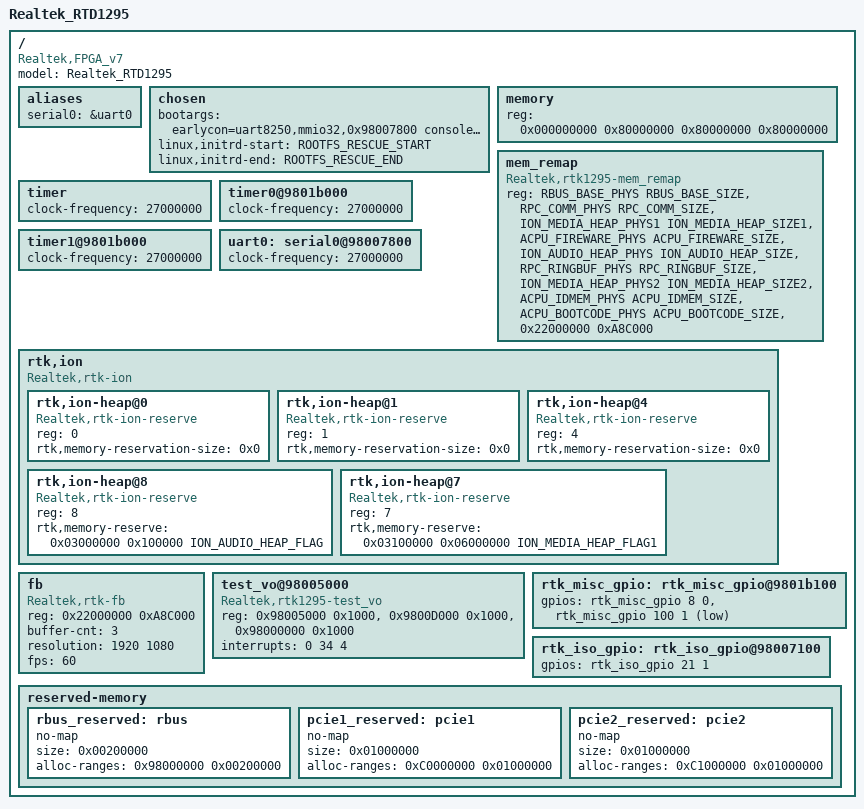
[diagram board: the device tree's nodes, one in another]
/dts-v1/;
#include "../../../../../include/soc/realtek/memory.h"

/memreserve/ SYS_BOOTCODE_MEMBASE       SYS_BOOTCODE_MEMSIZE        ; /* 0x00000000 ~ 0x00030000 */
/memreserve/ RPC_COMM_PHYS              RPC_COMM_SIZE               ; /* 0x0001f000 ~ 0x0001ffff */
/memreserve/ RESERVED_832KB_PHYS        RESERVED_832KB_SIZE         ; /* 0x00030000 ~ 0x000fffff */
/memreserve/ ACPU_FIREWARE_PHYS         ACPU_FIREWARE_SIZE          ; /* 0x01b00000 ~ 0x01efffff */
/memreserve/ RPC_RINGBUF_PHYS           RPC_RINGBUF_SIZE            ; /* 0x01ffe000 ~ 0x02001fff */
/memreserve/ ROOTFS_RESCUE_START        ROOTFS_RESCUE_SIZE          ; /* 0x02200000 ~ 0x02Dfffff */
/memreserve/ 0x22000000                 0x17BB000                   ; /* Framebuffer */
/memreserve/ 0x03000000                 0x00100000                  ; /* ?? */
/memreserve/ 0x03100000                 0x06000000                  ; /* ?? */
/memreserve/ ACPU_IDMEM_PHYS            ACPU_IDMEM_SIZE             ; /* 0x10000000 ~ 0x10013fff */
/memreserve/ ACPU_BOOTCODE_PHYS         ACPU_BOOTCODE_SIZE          ; /* 0x10000000 ~ 0x10013fff */
/memreserve/ HW_SECURE_RAM_START        HW_SECURE_RAM_SIZE          ; /* 32KB */
/memreserve/ HW_NOR_REMAP_START         HW_NOR_REMAP_SIZE           ; /* 32MB */
/memreserve/ HW_JTAG_GIC_RSV_START      HW_JTAG_GIC_RSV_SIZE        ; /* 8MB  */


#include "rtd-1296.dtsi"
#include "rtd-129x-dvfs.dtsi"

/ {
    model= "Realtek_RTD1295";
    compatible = "Realtek,FPGA_v7", "Realtek,rtd-1295";

    aliases {
        serial0 = &uart0;
    };

    chosen {
        bootargs = "earlycon=uart8250,mmio32,0x98007800 console=ttyS0,115200 cma=64m@576m init=/init androidboot.hardware=kylin androidboot.storage=emmc loglevel=4";
        linux,initrd-start = <ROOTFS_RESCUE_START>;
        linux,initrd-end = <ROOTFS_RESCUE_END>;
    };

    memory {
        device_type = "memory";
        reg = <0x000000000 0x80000000 0x80000000 0x80000000>; /* 4096 MB */
    };

    mem_remap {
        compatible = "Realtek,rtk1295-mem_remap";
        reg = <RBUS_BASE_PHYS RBUS_BASE_SIZE>,
              <RPC_COMM_PHYS RPC_COMM_SIZE>,
              <ION_MEDIA_HEAP_PHYS1 ION_MEDIA_HEAP_SIZE1>,
              <ACPU_FIREWARE_PHYS ACPU_FIREWARE_SIZE>,
              <ION_AUDIO_HEAP_PHYS ION_AUDIO_HEAP_SIZE>,
              <RPC_RINGBUF_PHYS RPC_RINGBUF_SIZE>,
              <ION_MEDIA_HEAP_PHYS2 ION_MEDIA_HEAP_SIZE2>,
              <ACPU_IDMEM_PHYS ACPU_IDMEM_SIZE>,
              <ACPU_BOOTCODE_PHYS ACPU_BOOTCODE_SIZE>,
              <0x22000000 0xA8C000>;
    };

    timer {
        clock-frequency = <27000000>;
    };

    timer0@9801b000 {
        clock-frequency = <27000000>;
    };

    timer1@9801b000 {
        clock-frequency = <27000000>;
    };

    uart0: serial0@98007800 {
        clock-frequency = <27000000>;
    };

    rtk,ion {
        compatible = "Realtek,rtk-ion";
        #address-cells = <1>;
        #size-cells = <0>;
        rtk,ion-heap@0 {    /* SYSTEM_HEAP */
            compatible = "Realtek,rtk-ion-reserve";
            reg = <0>;
            rtk,memory-reservation-size = <0x0>;
        };
        rtk,ion-heap@1 {    /* System contig */
            compatible = "Realtek,rtk-ion-reserve";
            reg = <1>;
            rtk,memory-reservation-size = <0x0>;
        };
        rtk,ion-heap@4 {    /* DMA_HEAP */
            compatible = "Realtek,rtk-ion-reserve";
            reg = <4>;
            rtk,memory-reservation-size = <0x0>;
        };
        rtk,ion-heap@8 {    /* Audio */
            compatible = "Realtek,rtk-ion-reserve";
            reg = <8>;
            rtk,memory-reserve = <
                0x03000000 0x100000 ION_AUDIO_HEAP_FLAG
                >;
        };
        rtk,ion-heap@7 {    /* TYPE_MEDIA */
            compatible = "Realtek,rtk-ion-reserve";
            reg = <7>;
            rtk,memory-reserve = <
                0x03100000 0x06000000 ION_MEDIA_HEAP_FLAG1
                >;
        };
    };

    fb {
        compatible = "Realtek,rtk-fb";
        reg = <0x22000000 0xA8C000>;
        buffer-cnt = <3>;
        resolution = <1920 1080>;
        fps = <60>;
    };

    test_vo@98005000 {
        compatible = "Realtek,rtk1295-test_vo";
        reg = <0x98005000 0x1000>, <0x9800D000 0x1000>, <0x98000000 0x1000>;
        //interrupts = <0 31 4>;
        interrupts = <0 34 4>;
    };

    rtk_misc_gpio: rtk_misc_gpio@9801b100 {
        gpios =
            <&rtk_misc_gpio 8 0 0>,         /* install button, input, default N/A */
            <&rtk_misc_gpio 100 1 1>;       /* audio dac unmute , output, default high */
    };

    rtk_iso_gpio: rtk_iso_gpio@98007100 {
        gpios =
            <&rtk_iso_gpio 21 1 0>;         /* igpio21, output, default low */
    };

    reserved-memory {
		#address-cells = <1>;
		#size-cells = <1>;
		ranges;

		rbus_reserved: rbus {
			no-map;
			size = <0x00200000>;
			alloc-ranges = <0x98000000 0x00200000>; 
		};

		pcie1_reserved: pcie1 {
			no-map;
			size = <0x01000000>;
			alloc-ranges = <0xC0000000 0x01000000>; 
		};

		pcie2_reserved: pcie2 {
			no-map;
			size = <0x01000000>;
			alloc-ranges = <0xC1000000 0x01000000>; 
		};
	};
};
